# ISP6P5_IPIPEIF register map
Vendor: Texas Instruments
Peripheral module from a debugger description file (folder DRA74xP_75xP_76xP_77xP).
Registers are 32-bit, access per field, reset 0x0 unless marked. A register's access mark holds for its fields unless they carry their own. Offsets are as the file gives them; lines under a group give offsets from that group; [hi:lo] are bit positions; {n}, {i} and the like mark numbered series; 'fields as' and 'values as' point back to an identical list; <NAME> marks a mode.

## ISP6P5_IPIPEIF
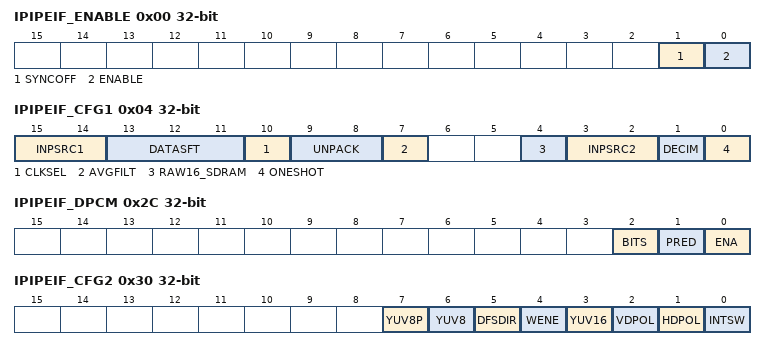
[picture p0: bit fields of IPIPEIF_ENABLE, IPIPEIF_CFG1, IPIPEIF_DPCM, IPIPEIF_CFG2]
0x00 IPIPEIF_ENABLE
  [1] SYNCOFF rw — VD output mask This register masks the VD output to the IPIPE module. This can be useful when one wants to read data from SDRAM which are stored in a double buffer. If the VD is not masked each time we start the module an new VD will be generated to the IPIPEIF module. Let's consider two buffers A and B of N lines each. *This bit field is latched by VD.
    0=DISABLE (VD output mask is disabled.); 1=ENABLE (VD output mask is enabled.)
  [0] ENABLE rw — IPIPE I/F Enable This register is used to start the operation of SDRAM buffer memory read and generates SYNC signals. This register is available when INPSRC1 or INPSCR2 = 1, 2 or 3.
    0=DISABLE (IPIPE SDRAM I/F Disabled); 1=ENABLE (IPIPE SDRAM I/F Enabled)
0x04 IPIPEIF_CFG1 — IPIPEIF Configuration #1
  [15:14] INPSRC1 rw — Selects the source for the mux (VPORT / ISIF / SDRAM) as well as the data format type.
    0=RAW (RAW data from VPORT); 1=SDRAM_RAW (RAW data from SDRAM); 3=SDRAM_YUV (YUV data from SDRAM); 2=ISIF_DARKFM (ISIF_DARKFM Dark frame subtration or WDR merge is selected. Input ports to DFS/WDR submodule are VPORT and SDRAM.)
  [13:11] DATASFT rw — SDRAM read data shift This register is available when INPSRC1 or INPSRC2 = 1 or 2, i.e., when data are read from SDRAM. If UNPACK = 1 or 2, this value must be 0, 1, 2, 3, or 4.
    6=If UNPACK=1 or 2, this value is invalid. If UNPACK=3 or (UNPACK=0 and RAW16=0) Output data[15:0] = '0000' read data[15:4] If UNPACK=0 and RAW16=1 Output data[15:0] = (read data[9:0]) '000000'; 1=If UNPACK 0 or RAW16=0 Output data[15:12] = '0000' Output data[11:0] = read data[10:0] '0'; If UNPACK=0 and RAW16=1 Output data[15:0] = (read data[14:0]) '0'; 7=If UNPACK=1 or 2, this value is invalid. If UNPACK=3 or (UNPACK=0 and RAW16=0) Output data[15:0] = '0000' read data[15:4] If UNPACK=0 and RAW16=1 Output data[15:0] = (read data[8:0]) '0000000'; 0=If UNPACK 0, or RAW16_SDRAM=0 Output data[15:12] = '0000' Output data[11:0] = read data[11:0] If UNPACK=0 and RAW16=1 Output data[15:0] = read data[15:0]; 2=If UNPACK 0 or RAW16=0 Output data[15:12] = '0000' Output data[11:0] = read data[9:0] '00' If UNPACK=0 and RAW16=1 Output data[15:0] = (read data[13:0]) '00'; 4=If UNPACK 0 or RAW16=0 Output data[15:12] = '0000' Output data[11:0] = read data[7:0] '0000' If UNPACK=0 and RAW16=1 Output data[15:0] = (read data[11:0]) '0000'; 5=If UNPACK=1 or 2, this value is invalid. If UNPACK=3 or (UNPACK=0 and RAW16=0) Output data[15:0] = '0000' read data[15:4] If UNPACK=0 and RAW16=1 Output data[15:0] = (read data[10:0]) '00000'; 3=If UNPACK 0 or RAW16=0 Output data[15:12] = '0000' Output data[11:0] = read data[8:0] '000' If UNPACK=0 and RAW16=1 Output data[15:0] = (read data[12:0]) '000'
  [10] CLKSEL rw — IPIPEIF IPIPE module pixel clock selection. This register shall be set to '1' when INPSRC1 or INPSRC2 = 1 or 3, i.e., data are solely read from SDRAM (VPORT inactive).
    0=PCLK (Selects the pixel clock from the VPORT.); 1=SDRAM_DIV_CLK (Selects the pixel clock from the fractional clock divider. The fractional clock divider value is setup with the register.)
  [9:8] UNPACK rw — 8-Bit, 12-bit Packed Mode When sensor raw data are stored in 8-bit packed mode or 12-bit packed mode, this register should code 1 or 3. This register is effective when INPSRC = 1 or 2.
    0=NORMAL_16_BITS_PIXEL (16 bits / pixel); 1=PACK_8_BITS_PIXEL (8 bits / pixel); 3=PACK_12_BITS_PIXEL (12 bits / pixel); 2=PACK_8_BITS_PIXEL_ALAW (8 bits / pixel + inverse A law (8 bits to 10 bits))
  [7] AVGFILT rw — Averaging Filter It applies (1,2,1) filter for the RGB/YCbCr data. *This bit field is latched by VD.
    0=OFF; 1=ON
  [4] RAW16_SDRAM rw — RAW16/12 format of SDRAM This affect how DATASFT works. This bit is valid if UNPCK=0.
  [3:2] INPSRC2 rw — Selects the source for the mux (ISIF / SDRAM) as well as the data format type.
    0=ISIF; 1=SDRAM_RAW (from SDRAM (raw data)); 3=SDRAM_YUV (from SDRAM (YUV data)); 2=ISIF_DARKFM (Dark frame subtration or WDR merge is selected. from ISIF SDRAM (Darkframe Subtraction : DFS, or WDR merge))
  [1] DECIM rw — Pixel Decimation The decimation rate defined by RSZ register. *This bit field is latched by VD.
    0=NODECIMATION; 1=DECIMATE (Decimation)
  [0] ONESHOT rw — One Shot Mode This register is available when INPSRC = 1 or 3.
    0=CONTINUOUS (Continuous mode); 1=ONESHOT (One shot mode)
0x08 IPIPEIF_PPLN — IPIPEIF Interval of HD / Start pixel in HD
  [12:0] PPLN rw — Case-1: Interval of Horizontal Sync (HD) Specifies the interval of horizontal sync. This register is available when INPSRC = 1 or 3. Case-2: Start Pixel in Horizontal Sync (HD) Specifies the start pixel in horizontal sync. This register is available when INPSRC = 2 *This bit field is latched by VD.
0x0C IPIPEIF_LPFR — IPIPEIF Interval of VD / Start line in VD
  [12:0] LPFR rw — Case-1: Interval of Vertical Sync (VD) Specifies the interval of vertical sync. This register is available when INPSRC = 1 or 3. Case-2: Start Pixel in Vertical Sync (VD) Specifies the start line in vertical sync. This register is available when INPSRC = 2 *This bit field is latched by VD.
0x10 IPIPEIF_HNUM — IPIPEIF Number of valid pixels per line
  [12:0] HNUM rw — The Number of Valid Pixels in a Line Specifies the number of valid pixels in a horizontal line. This register is available when INPSRC = 1, 2 or 3 *This bit field is latched by VD.
0x14 IPIPEIF_VNUM — IPIPEIF Number of valid lines per frame
  [12:0] VNUM rw — The Number of Valid Line in a Vertical Specifies the number of valid line in a vertical. This register is available when INPSRC = 1, 2 or 3 *This bit field is latched by VD.
0x18 IPIPEIF_ADDRU — IPIPEIF Memory Address (Upper)
  [10:0] ADDRU rw — Memory Address ? Upper Memory address upper 11-bits are specified in units of 32-bytes This register is available when INPSRC = 1, 2 or 3. *This bit field is latched by VD.
0x1C IPIPEIF_ADDRL — IPIPEIF Memory Address (Lower)
  [15:0] ADDRL rw — Memory Address - Lower Memory address lower 16-bits are specified in units of 32-bytes. This register is available when INPSRC = 1, 2 or 3. *This bit field is latched by VD.
0x20 IPIPEIF_ADOFS — IPIPEIF Address offset
  [11:0] ADOFS rw — Specifies the SDRAM stride for each line in units of 32-bytes. This register is available when reading data from SDRAM: INPSRC1 or INPSRC2 = 1, 2 or 3. Assuming that the first line is at position ADDR, the second line is at address ADDR+ ADOFS, etc. *This bit field is latched by VD.
0x24 IPIPEIF_RSZ reset 0x10 — IPIPEIF Horizontal Resizing Parameter on IPIPE datapath
  [6:0] RSZ rw — Horizontal Resizing Parameter for IPIPE datapath Specifies the horizontal resizing parameter. The RSZ register can be configured within 16 to 112 range. This resizing ratio is determined by 16/RSZ (= 1/1 to 1/7) *This bit field is latched by VD.
0x28 IPIPEIF_GAIN reset 0x200 — IPIPEIF Gain Parameter
  [9:0] GAIN rw — Gain Parameter Specifies the gain applied to RAW data before it is forwarded to the IPIPE module. The gain value is expressed using the U10Q9 fractional format. The range is from 0.00195 (1/512) to 1.99805(1023/512). By default the unity gain is applied, i.e.,IPIPEIF_GAIN.GAIN = 0x200. The gain is applied to RAW data only (IPIPEIF_CFG1.INPSRC2 != 3): the gain is not applied if the input data is YCbCr. *This bit field is latched by VD.
0x2C IPIPEIF_DPCM — IPIPEIF DPCM configuration This register applies only if.UNPACK = 1, i.e., RAW8 data is read from SDRAM. This register access is enabled by the Nokia Custom key
  [2] BITS rw — DPCM bit mode for SDRAM data This register access is enabled by the Nokia Custom key
    0=_8TO10 (8bit to 10bit DPCM decompression); 1=_8TO12 (8bit to 12bit DPCM decompression)
  [1] PRED rw — DPCM prediction mode for SDRAM data This register access is enabled by the Nokia Custom key
    0=SIMPLE (Simple predictor); 1=ADVANCED (Advanced predictor)
  [0] ENA rw — DPCM decompression enable for SDRAM data.
    0=OFF (DPCM off (no decompression)); 1=ON (DPCM on)
0x30 IPIPEIF_CFG2 — IPIPEIF Configuration #2
  [7] YUV8P rw — 8-bit YUV data unpacking to 16 bits WhenIPIPEIF_CFG1.INPSRC2 = 0 and IPIPEIF_CFG2.YUV16 = 1, the 8-bit YUV data are transformed into 16-bit YUV data. The way the data are unpacked from 8 bits to 16 bits is controlled by the IPIPEIF_CFG2.YUV8P register. The upper 8 bits of the 16-bit output are set to 0.
    0=Y (Y output on even pixels C output on odd pixels); 1=C (C output on even pixels Y output on odd pixels)
  [6] YUV8 rw — YUV 8bit mode When ISIF_CFG1.INPSRC2 = 0 and YUV16 = 1, setting this bit to 1 enables the conversion from 8bit YUV input to 16bit YUV. This register is used when the input data from the ISIF module is 8-bit YUV data.
    0=YUV16 (YUV16 input); 1=YUV8 (YUV 8bit input This value is not allowed if.INPSRC1=1 and .INPSRC2=0)
  [5] DFSDIR rw — DFS direction Selects the direction of dark frame subtraction.
    0=VPORT (In DFS mode VPORT IF(capture frame) - SDRAM (dark frame) In WDR mode Long Exposure: VPORT, Short Exposure: SDRAM); 1=SDRAM (In DFS mode SDRAM (capture frame) - VPORT IF(dark frame) In WDR mode Long Exposure: SDRAM, Short Exposure: VPORT)
  [4] WENE rw — External WEN signal selection Do not use for OMAP4 and MONICA since there is not parallel interface at chip level. This register shall always be set to 0.
    0=NO_EXTERNAL_WEN (do not use external WEN); 1=EXTERNAL_WEN (use external WEN)
  [3] YUV16 rw — Data type selection. The behavior of this bitfield depends upon other register settings. The functionality is best explained with the following pseudo code: if ((CFG1.INPSRC2==0 CFG2.YUV16) || CFG1.INPSRC2==3) { data_out[15:0] = yuv[15:0] } else if (CFG1.INPSRC2==1 CFG2.YUV16 CFG1.UNPACK=1) { data_out[15:8] = gain_clip[7:0]; data_out[ 7:0] = 0; } else { data_out[15: 0] = gain_clip[15:0]; } where: o data_out[15:0] = 16bit yuv or 16bit raw data to ipipe o yuv[15:0] = 16bit yuv data from 'horizontal pixel decimator' block. o gain_clip[15:0] = 16bit raw data from 'gain' block.
    0=RAW (12-bit RAW data); 1=YUV (16-bit YUV data)
  [2] VDPOL rw — VD Sync Polarity When input VD is active low SYNC pulse, this bit needs to be set to ?1?.
    0=POSITIVE; 1=NEGATIVE
  [1] HDPOL rw — HD Sync Polarity When input HD is active low SYNC pulse, this bit needs to be set to ?1?.
    0=POSITIVE; 1=NEGATIVE
  [0] INTSW rw — IPIPEIF interrupt source selection. This register select the interrupt source.
    0=VPORT (Start position of VD from VPORT interface); 1=ISIF (Start position of VD from ISIF module)
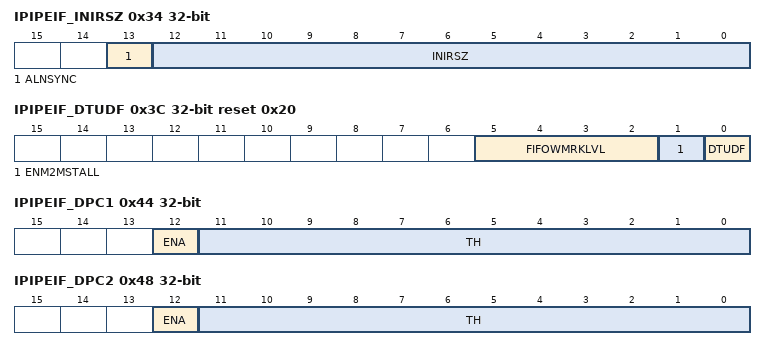
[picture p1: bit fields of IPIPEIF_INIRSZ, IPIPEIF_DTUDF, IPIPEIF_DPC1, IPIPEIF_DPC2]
0x34 IPIPEIF_INIRSZ — IPIPEIF resize initial position - IPIPE data path. This value is not used in the c-model, as C-model expects the first pixel postion is the same as the first input pixel. To match HW with C-model, INIRSZ must be equal to the cycles between HD and the first cycle. In FDS/WDR mode, INIRSZ=PPLN
  [13] ALNSYNC rw — Align the HSYNC,VSYNC to initial position defined by INIRSZ.
    0=DISABLE; 1=ENABLE
  [12:0] INIRSZ rw — Offset used to re-initialize the HD/VD position after resizer. From 0 to 8191 PCLK cycles.
0x38 IPIPEIF_OCLIP reset 0xFFF — IPIPEIF output clipping value
  [15:0] OCLIP rw — Output clipping value after gain control on IPIPE data path. This value is in U16Q0 data format. For nomarl mode, this value should be 0 OCLIP 4096 For WDR mode, this value should be 0 OCLIP 65536
0x3C IPIPEIF_DTUDF reset 0x20 — IPIPEIF data underflow detection
  [5:2] FIFOWMRKLVL rw — To guarantee that the FIFO does not overflow, the stall request is deasserted only when a certain number of locations in the FIFO are free. The number of free locations is configurable. A safe number of mandatory free locations can be configured by taking into consideration the pixel clock frequency (PCLK) with respect to that of the functional clock (FUNC CLK). The worst case occurs when PCLK = FUNC CLK. In that case, value should be configured to 0 (i.e. 16 free locations) so that the stall will be deasserted only when the 16-deep FIFO is completely empty.
    {v}=Stall deassertion when FIFO has not more than {v} valid entry and SDRAM data available (v=1..15); 0=Stall deassertion when FIFO is empty (16 free locations) and SDRAM data available
  [1] ENM2MSTALL rw — Enable memory-to-memory stall mechanism
    0=DISABLE (disable (no special stall mechanism for memory-to-memory use cases)); 1=ENABLE (enable (stall mechanism for memory-to-memory use cases))
  [0] DTUDF rw — Data under flow error status register. Reading ?1? shows there is data under flow and at least one data is corrupted while reading from SDRAM. Writing ?1? to this register clears (=0) the error (=1) status. Underflow errors are non recoverable at ISP5 level, need to do a soft reset at ISS level. The IPIPEIF_UDF interrupt is generated when an underflow happens. The interrupt avoids polling this register for errors. If ENM2MSTALL is enabled, then programmers need to ensure that the SW does not clear DTUDF[0] as this would reset the MTC read interface. DTUDF[0] can be cleared only in the on-the-fly operation where the stall mechanism will not work.
0x40 IPIPEIF_CLKDIV reset 0x1 — IPIPEIF CLOCK DIVIDER
  [15:0] CLKDIV rw — IPIPEIF clock rate configuration IPIPE/IPIPEIF clock frequency = M/N x clk_vpss clock frequency. We have M = CLKDIV[15:8] + 1 and N = CLKDIV[7:0] + 1 This register is available whenIPIPEIF_CFG1.CLKSEL = 1.
0x44 IPIPEIF_DPC1 — IPIPEIF defect pixel correction #1
  [12] ENA rw — DPC enable. Applies DPC for video port data, ISIF input path.
    0=DISABLE; 1=ENABLE
  [11:0] TH rw — DPC threshold value
0x48 IPIPEIF_DPC2 — IPIPEIF defect pixel correction #2
  [12] ENA rw — DPC enable. Applies DPC for SDRAM input path.
    0=DISABLE; 1=ENABLE
  [11:0] TH rw — DPC threshold value
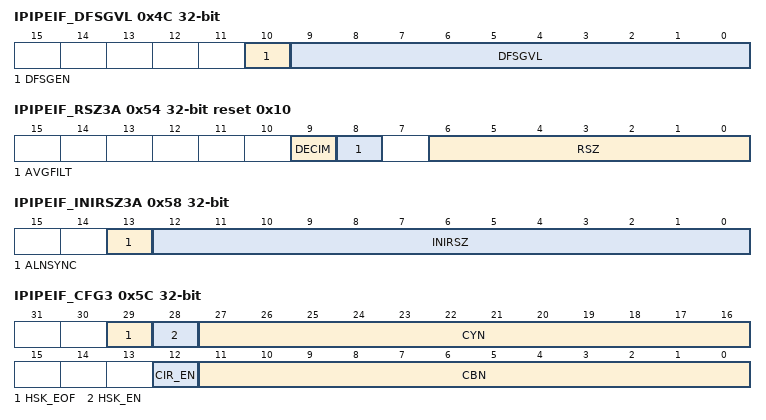
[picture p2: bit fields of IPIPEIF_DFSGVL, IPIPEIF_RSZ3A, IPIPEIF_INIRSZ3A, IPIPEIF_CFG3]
0x4C IPIPEIF_DFSGVL — IPIPEIF DARK FRAME GAIN CONTROL - GAIN VALUE
  [10] DFSGEN rw — DFS gain control enable. This functionality is protected by an eFuse. Not available when ISP5_EFUSE4_EN = '0'.
  [9:0] DFSGVL rw — DFS gain value. This functionality is protected by an eFuse. Not available when ISP5_EFUSE4_EN = '0'.
0x50 IPIPEIF_DFSGTH reset 0xFFF — IPIPEIF DARK FRAME GAIN CONTROL - THRESHOLD VALUE
  [11:0] DFSGTH rw — DFS gain threshold value. This functionality is protected by an eFuse. Not available when ISP5_EFUSE4_EN = '0'.
0x54 IPIPEIF_RSZ3A reset 0x10 — IPIPEIF HORIZONTAL RESIZING PARAMETER FOR H3A
  [9] DECIM rw — Pixel Decimation Enable The decimation rate defined by the RSZ bitfield. *This bit field is latched by VD.
    0=DISABLE (No Decimation); 1=ENABLE (Decimate)
  [8] AVGFILT rw — Averaging Filter It applies a (1, 2, 1) filter for the RGB/YCbCr data. *This bit field is latched by VD.
    0=DISABLE; 1=ENABLE
  [6:0] RSZ rw — Horizontal Resizing Parameter for H3A datapath Specifies the horizontal resizing parameter. The RSZ register can be configured within 16 to 112 range. This resizing ratio is determined by 16/RSZ (= 1/1 to 1/7) *This bit field is latched by VD.
0x58 IPIPEIF_INIRSZ3A — IPIPEIF resize initial position - H3A data path.
  [13] ALNSYNC rw — Align the HD, VD to initial position defined by the INIRSZ bit field. It means that HD and VD are effectivly shifted by INIRSZ pixel clock cycles.
    0=DISABLE; 1=ENABLE
  [12:0] INIRSZ rw — Offset used to re-initialize the HD/VD position after resizer. From 0 to 8191 PCLK cycles.
0x5C IPIPEIF_CFG3 — Parameters for Circular buffering
  [29] HSK_EOF rw — Issue C_DONE at the end of frame. If this function is on, C_DONE is issued at the end of frame even if the last line not N-th line in ICM handshake sequence. If the last line is N-th line, C_DONE is issued regardless of this bit. *This bit field is latched by VD.
    0=DISABLE (Disable C_DONE at the end of frame, unless it is the Nth line of ICM handshake proess.); 1=ENABLE (Enalble output of C_DONE at the enf of frame.)
  [28] HSK_EN rw — Handshake with ICM is enabled Note: If ICM handshake is on in DFS/WDR mode (INPSRC1=2 or INPSRC2=2), memory-to-memory stall mechanism must be on (IPIPEIF_DTUDF.ENM2MSTALL=1) *This bit field is latched by VD.
    0=DISABLE (Handshake with ICM is disabled); 1=ENABLE (Handshake with ICM is enabled)
  [27:16] CYN rw — ICM Handshake cycle U12 *This bit field is latched by VD.
  [12] CIR_EN rw — Enable circular buffering *This bit field is latched by VD.
    0=DISABLE (Circular buffering disabled); 1=ENABLE (Circular buffer enabled)
  [11:0] CBN rw — Circular buffer cycle U12 *This bit field is latched by VD.
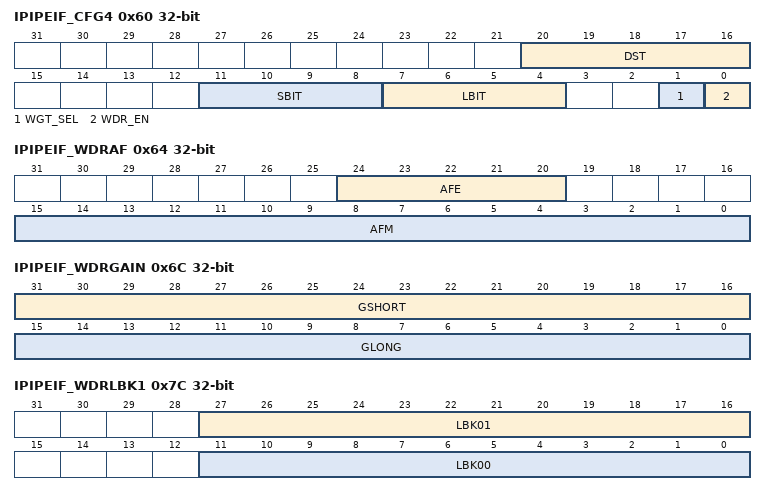
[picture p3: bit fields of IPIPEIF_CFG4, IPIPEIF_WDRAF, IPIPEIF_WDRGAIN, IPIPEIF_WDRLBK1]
0x60 IPIPEIF_CFG4 — IPIPEIF WDR configuration for WDR merging
  [20:16] DST rw — Down shift value after WDR merge *This bit field is latched by VD.
  [11:8] SBIT rw — Shift up value for short exposure pixel Usually set (16- (bit width of long exposure pixels)). For example, if the input is 12 bit, set 4 here. *This bit field is latched by VD.
  [7:4] LBIT rw — Shift up value for long exposure pixel Usually set (16- (bit width of long exposure pixels)). For example, if the input is 12 bit, set 4 here. *This bit field is latched by VD.
  [1] WGT_SEL rw — Select the source for weight calculation in WDR merge *This bit field is latched by VD.
    0=LONG (Use long_exposure pixel for weight calculation); 1=SHORT (Use short exposure value for weight calculation.)
  [0] WDR_EN rw — Enable WDR merge (Two frame/single frame) When this function is enabled, WDR is used instead of DFS. *This bit field is latched by VD.
    0=DISABLE (DISABLE WDR merging function.); 1=ENABLE (ENABLE WDR function. WDR overtake DFS function.)
0x64 IPIPEIF_WDRAF — WDR Merge parameter AF_M
  [24:20] AFE rw — WDR Merge parameter AFE Exponential part of a value in weight calculation Unsigned 5bit *This bit field is latched by VD.
  [15:0] AFM rw — WDR Merge parameter AF_M Coefficient (mantissa) part of a value in weight calculation Signed 16bit *This bit field is latched by VD.
0x68 IPIPEIF_WDRBF — WDR Merge parameter BF
  [15:0] BF rw — WDR Merge parameter BF Q0.15) The actual value is BF x 2^-16 x 2^-5 *This bit field is latched by VD.
0x6C IPIPEIF_WDRGAIN rw — Gain difference between long exposure and short exposure
  [31:16] GSHORT — The gain applied to short exposure pixels. (U1.15) Usually, this value is 32768 *This bit field is latched by VD. For example, if the gain difference is x4, GDIFF = 8192
  [15:0] GLONG — The gain applied to long exposure pixels. (U1.15) Usually, this value is GLONG = 32768 * (short exposure gain in camera)/(long exposure gain in camera) *This bit field is latched by VD. For example, if the gain difference is x4, GDIFF = 8192
0x70 IPIPEIF_WDRTHR — Threshold value in WDR merging
  [15:0] THR rw — T (Threshold value) U16 *This bit field is latched by VD.
0x74 IPIPEIF_RSVD1 ro — White Balance used in weight calculation
0x78 IPIPEIF_RSVD2 ro
0x7C IPIPEIF_WDRLBK1 — Black level for Long exposure input
  [27:16] LBK01 rw — Black level for long exposure pixel at [0, 1] (Odd pixel at even line) U12 *This bit field is latched by VD.
  [11:0] LBK00 rw — Black level for long exposure pixel at [0, 0] (Even pixel at even line) U12 *This bit field is latched by VD.
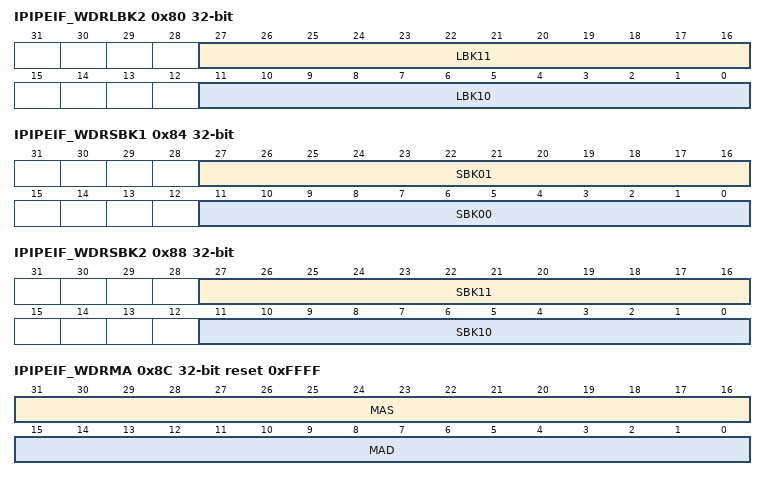
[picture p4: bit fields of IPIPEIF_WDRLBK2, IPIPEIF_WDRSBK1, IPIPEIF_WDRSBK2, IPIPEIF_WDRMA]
0x80 IPIPEIF_WDRLBK2 — Black level for Long exposure input
  [27:16] LBK11 rw — Black level for long exposure pixel at [1, 1] (Odd pixel at odd line) U12 *This bit field is latched by VD.
  [11:0] LBK10 rw — 1lack level for long exposure pixel at [1, 0 ] (Even pixel at odd line) U12 *This bit field is latched by VD.
0x84 IPIPEIF_WDRSBK1 — Black level for short exposure input
  [27:16] SBK01 rw — Black level for short exposure pixel at [0, 1] (Odd pixel at even line) U12 *This bit field is latched by VD.
  [11:0] SBK00 rw — Black level for short exposure pixel at [0, 0] (Even pixel at even line) U12 *This bit field is latched by VD.
0x88 IPIPEIF_WDRSBK2 — Black level for short exposure input
  [27:16] SBK11 rw — Black level for short exposure pixel at [1, 1] (Odd pixel at odd line) U12 *This bit field is latched by VD.
  [11:0] SBK10 rw — 1lack level for short exposure pixel at [1, 0 ] (Even pixel at odd line) U12 *This bit field is latched by VD.
0x8C IPIPEIF_WDRMA rw reset 0xFFFF — Threshold value in motion adaptive filter
  [31:16] MAS — Slope in motion adaptive filter MAS = 32768/(D2-D1) U16 *This bit field is latched by VD.
  [15:0] MAD — Threshold (D1) in motion adaptive filter U16 To disable MA filtering, put the maximum value (65535: default) *This bit field is latched by VD.
0x90 IPIPEIF_WDRSAT_VP reset 0xFFFFF — Saturation parameters for VPORT input
  [19:0] VP_SAT rw — Saturation value for VPORT input used in WDR split function for pseudo-long-exposure image Do disable, set maximum value (1048575: default) *This bit field is latched by VD.
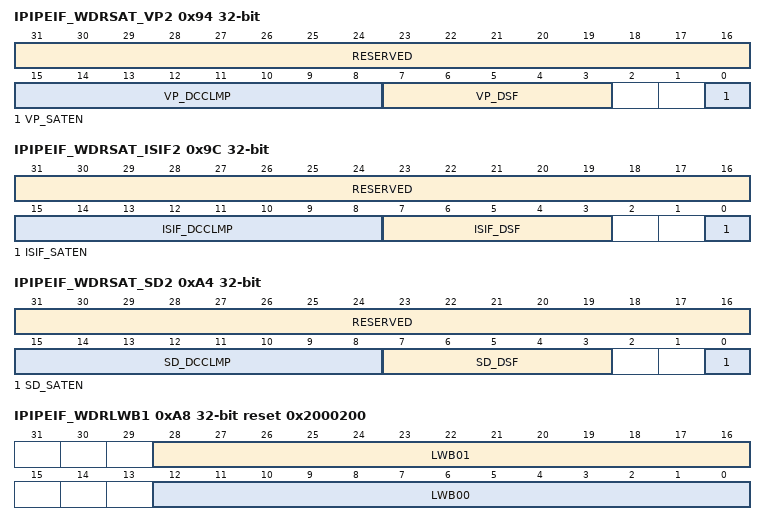
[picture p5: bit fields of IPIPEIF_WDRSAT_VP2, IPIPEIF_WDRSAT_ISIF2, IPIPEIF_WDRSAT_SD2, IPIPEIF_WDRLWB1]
0x94 IPIPEIF_WDRSAT_VP2 — Saturation parameters for VPORT input
  [31:16] RESERVED ro
  [15:8] VP_DCCLMP rw — DC Clamp addition value for VPORT input (Used in WDR split function for pseudo-short-exposure) *This bit field is latched by VD.
  [7:3] VP_DSF rw — Down shift value for VPORT input (Used in WDR split function for pseudo-short-exposure) *This bit field is latched by VD.
  [0] VP_SATEN rw — Enable saturation function on VPort *This bit field is latched by VD.
    0=DISABLE (Saturation/Down shift on VPORT input is disabled); 1=ENABLE (Saturation/Down shift on VPORT input is enabled)
0x98 IPIPEIF_WDRSAT_ISIF reset 0xFFFFF — Saturation parameters for ISIF input
  [19:0] ISIF_SAT rw — Saturation value for ISIF input used in WDR split function for pseudo-long-exposure image Do disable, set maximum value (1048575: default) *This bit field is latched by VD.
0x9C IPIPEIF_WDRSAT_ISIF2 — Saturation value for ISIF input
  [31:16] RESERVED ro
  [15:8] ISIF_DCCLMP rw — DC Clamp addition value for ISIF input (Used in WDR split function for pseudo-short-exposure) *This bit field is latched by VD.
  [7:3] ISIF_DSF rw — Down shift value for ISIF input (Used in WDR split function for pseudo-short-exposure) *This bit field is latched by VD.
  [0] ISIF_SATEN rw — Enable saturation function on ISIF port *This bit field is latched by VD.
    0=DISABLE (Saturation/Down shift on ISIF input is disabled); 1=ENABLE (Saturation/Down shift on ISIF input is enabled)
0xA0 IPIPEIF_WDRSAT_SD reset 0xFFFFF — Saturation parameters for SDRAM input
  [19:0] SD_SAT rw — Saturation value for SDRAM input used in WDR split function for pseudo-long-exposure image Do disable, set maximum value (1048575: default) *This bit field is latched by VD.
0xA4 IPIPEIF_WDRSAT_SD2 — Saturation params for SDRAM input
  [31:16] RESERVED ro
  [15:8] SD_DCCLMP rw — DC Clamp addition value for SD Port input (Used in WDR split function for pseudo-short-exposure) *This bit field is latched by VD.
  [7:3] SD_DSF rw — Down shift value for SDRAM input (Used in WDR split function for pseudo-short-exposure) *This bit field is latched by VD.
  [0] SD_SATEN rw — Enable saturation function on SDRAM *This bit field is latched by VD.
    0=DISABLE (Saturation/Down shift on SDRAM input is disabled); 1=ENABLE (Saturation/Down shift on SDRAM input is enabled)
0xA8 IPIPEIF_WDRLWB1 reset 0x2000200 — White Balance used in weight calculation
  [28:16] LWB01 rw — White balance for pixels at [0, 1] (Odd pixel at even line) U4.9 (for gain=1.0, set 512) *This bit field is latched by VD.
  [12:0] LWB00 rw — White balance for pixels at [0, 0] (Even pixel at even line) U4.9 (for gain=1.0, set 512) *This bit field is latched by VD.
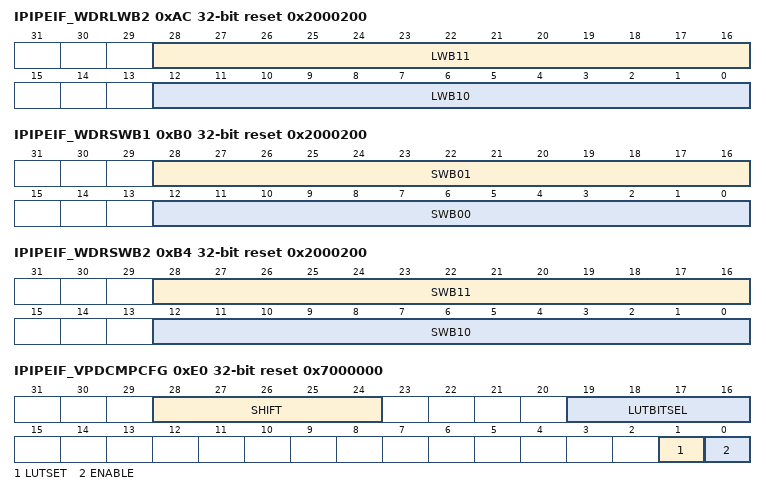
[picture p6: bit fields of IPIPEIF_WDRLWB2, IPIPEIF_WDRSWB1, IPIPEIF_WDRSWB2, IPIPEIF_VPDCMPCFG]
0xAC IPIPEIF_WDRLWB2 reset 0x2000200 — White Balance used in weight calculation
  [28:16] LWB11 rw — White balance for pixels at [0, 1] (Odd pixel at odd line) U4.9 (for gain=1.0, set 512) *This bit field is latched by VD.
  [12:0] LWB10 rw — White balance for pixels at [1, 0] (Even pixel at odd line) U4.9 (for gain=1.0, set 512) *This bit field is latched by VD.
0xB0 IPIPEIF_WDRSWB1 reset 0x2000200 — White Balance used in weight calculation
  [28:16] SWB01 rw — White balance for pixels at [0, 1] (Odd pixel at even line) U4.9 (for gain=1.0, set 512) *This bit field is latched by VD.
  [12:0] SWB00 rw — White balance for pixels at [0, 0] (Even pixel at even line) U4.9 (for gain=1.0, set 512) *This bit field is latched by VD.
0xB4 IPIPEIF_WDRSWB2 reset 0x2000200 — White Balance used in weight calculation
  [28:16] SWB11 rw — White balance for pixels at [0, 1] (Odd pixel at odd line) U4.9 (for gain=1.0, set 512) *This bit field is latched by VD.
  [12:0] SWB10 rw — White balance for pixels at [1, 0] (Even pixel at odd line) U4.9 (for gain=1.0, set 512) *This bit field is latched by VD.
0xB8 IPIPEIF_VPDCMPXTHR1 reset 0xFFF — Threshold value in VP Decomanding
  [15:0] XTHR1 rw — X_THR_1 (Threshold value) U16 *This bit field is latched by VD.
0xBC IPIPEIF_VPDCMPXTHR2 reset 0xFFFF — Threshold value in VP Decompanding
  [15:0] XTHR2 rw — X_THR_2 (Threshold value) U16 *This bit field is latched by VD.
0xC0 IPIPEIF_VPDCMPXTHR3 reset 0xFFFF — Threshold value in VP Decompanding
  [15:0] XTHR3 rw — X_THR_2 (Threshold value) U16 *This bit field is latched by VD.
0xC4 IPIPEIF_VPDCMPYTHR1 reset 0xFFF — Threshold value in VP Decomanding
  [19:0] YTHR1 rw — Y_THR_1 (Threshold value) U20 *This bit field is latched by VD.
0xC8 IPIPEIF_VPDCMPYTHR2 reset 0xFFFFF — Threshold value in VP Decomanding
  [19:0] YTHR2 rw — Y_THR_2 (Threshold value) U20 *This bit field is latched by VD.
0xCC IPIPEIF_VPDCMPYTHR3 reset 0xFFFFF — Threshold value in VP Decomanding
  [19:0] YTHR3 rw — Y_THR_3 (Threshold value) U20 *This bit field is latched by VD.
{0xCC+4i} IPIPEIF_VPDCMPSLOPE{i} reset 0x80 (i=1..4) — Slope value in VP Decomanding
  [15:0] SLOPE{i} rw — SLOPE_{i} (Slope value) U16 *This bit field is latched by VD.
0xE0 IPIPEIF_VPDCMPCFG reset 0x7000000 — Configuration register for VP Decomanding
  [28:24] SHIFT rw — Shift value for PWL U5 *This bit field is latched by VD.
  [19:16] LUTBITSEL rw — LUTBITSEL (For selecting address to LUT) U4 *This bit field is latched by VD.
  [1] LUTSET rw — Select Bit '0' : Choose PWL '1' : Choose LUT *This bit field is latched by VD.
  [0] ENABLE rw — Enable for VP Decompanding *This bit field is latched by VD.
0xE4 IPIPEIF_SDDCMPXTHR1 reset 0xFFF — Threshold value in SD Decomanding
  fields as IPIPEIF_VPDCMPXTHR1
0xE8 IPIPEIF_SDDCMPXTHR2 reset 0xFFFF — Threshold value in SD Decompanding
  fields as IPIPEIF_VPDCMPXTHR2
0xEC IPIPEIF_SDDCMPXTHR3 reset 0xFFFF — Threshold value in SD Decompanding
  fields as IPIPEIF_VPDCMPXTHR3
0xF0 IPIPEIF_SDDCMPYTHR1 reset 0xFFF — Threshold value in SD Decomanding
  fields as IPIPEIF_VPDCMPYTHR1
0xF4 IPIPEIF_SDDCMPYTHR2 reset 0xFFFFF — Threshold value in SD Decomanding
  fields as IPIPEIF_VPDCMPYTHR2
0xF8 IPIPEIF_SDDCMPYTHR3 reset 0xFFFFF — Threshold value in SD Decomanding
  fields as IPIPEIF_VPDCMPYTHR3
{0xF8+4i} IPIPEIF_SDDCMPSLOPE{i} reset 0x80 (i=1..4) — Slope value in SD Decomanding
  fields as IPIPEIF_VPDCMPSLOPE1
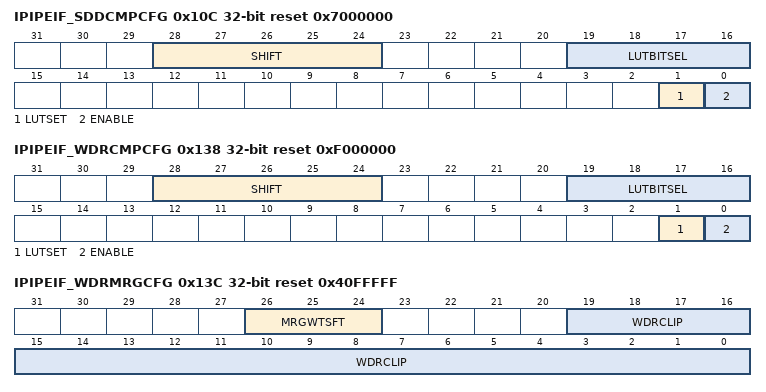
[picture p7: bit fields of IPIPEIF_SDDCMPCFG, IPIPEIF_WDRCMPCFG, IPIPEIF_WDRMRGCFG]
0x10C IPIPEIF_SDDCMPCFG reset 0x7000000 — Configuration register for SD Decomanding
  fields as IPIPEIF_VPDCMPCFG
0x110 IPIPEIF_WDRCMPXTHR1 reset 0xFFF — Threshold value in SD WDR Companding
  [19:0] XTHR1 rw — X_THR_1 (Threshold value) U16 *This bit field is latched by VD.
0x114 IPIPEIF_WDRCMPXTHR2 reset 0xFFFFF — Threshold value in WDR Companding
  [19:0] XTHR2 rw — X_THR_2 (Threshold value) U16 *This bit field is latched by VD.
0x118 IPIPEIF_WDRCMPXTHR3 reset 0xFFFFF — Threshold value in WDR Decompanding
  [19:0] XTHR3 rw — X_THR_2 (Threshold value) U16 *This bit field is latched by VD.
0x11C IPIPEIF_WDRCMPYTHR1 reset 0xFFF — Threshold value in WDR Companding
  [15:0] YTHR1 rw — Y_THR_1 (Threshold value) U20 *This bit field is latched by VD.
0x120 IPIPEIF_WDRCMPYTHR2 reset 0xFFFF — Threshold value in WDR Decompanding
  [15:0] YTHR2 rw — Y_THR_2 (Threshold value) U20 *This bit field is latched by VD.
0x124 IPIPEIF_WDRCMPYTHR3 reset 0xFFFF — Threshold value in WDR Companding
  [15:0] YTHR3 rw — Y_THR_3 (Threshold value) U20 *This bit field is latched by VD.
{0x124+4i} IPIPEIF_WDRCMPSLOPE{i} reset 0x8000 (i=1..4) — Slope value in WDR Decompanding
  [15:0] SLOPE1 rw — SLOPE_1 (Slope value) U16 *This bit field is latched by VD.
0x138 IPIPEIF_WDRCMPCFG reset 0xF000000 — Configuration register for WDR Decompanding
  fields as IPIPEIF_VPDCMPCFG
0x13C IPIPEIF_WDRMRGCFG reset 0x40FFFFF — Configuration register for WDR Merge
  [26:24] MRGWTSFT rw — Shift value for Weight black U3 *This bit field is latched by VD.
  [19:0] WDRCLIP rw — Clip value after WDR Merge *This bit field is latched by VD.
